# earlgrey register map
Vendor: lowRISC; File version: 0.1
CPU: ibex rev01, little endian, no MPU, no FPU, VTOR, 2 interrupt priority bits, 2 interrupts
Registers are 32-bit, read-write, no defined reset value unless marked. A register's access mark holds for its fields unless they carry their own. Offsets are from the block's base; [hi:lo] are bit positions.

## CSRNG — Takes entropy bits to produce cryptographically secure random numbers for consumption by hardware blocks and by software
Base 0x41150000
0x40 REGWEN — Register write enable for all control registers
  [0] Value — When true, all writeable registers can be modified.When false, they become read-only.
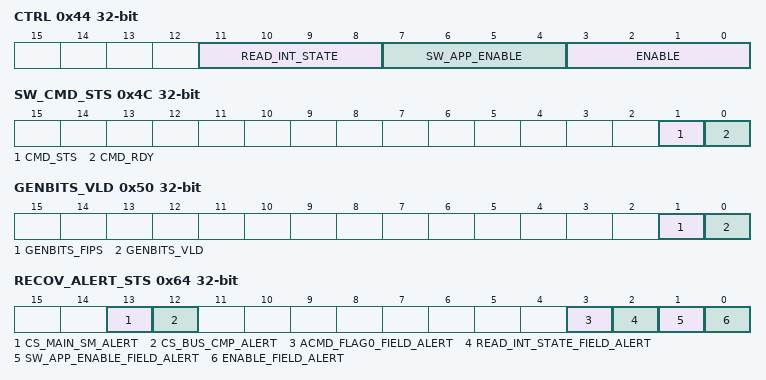
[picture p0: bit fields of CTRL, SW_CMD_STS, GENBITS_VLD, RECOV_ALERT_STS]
0x44 CTRL — Control register
  [11:8] READ_INT_STATE — Setting this field to kMultiBitBool4True will enable reading from the !!INT_STATE_VAL register.Reading the internal state of the enable instances will be enabledonly if the otp_en_csrng_sw_app_read input vector is set to the enable encoding.
  [7:4] SW_APP_ENABLE — Setting this field to kMultiBitBool4True will enable reading from the !!GENBITS register.This application interface for software (register based) will be enabledonly if the otp_en_csrng_sw_app_read input vector is set to the enable encoding.
  [3:0] ENABLE — Setting this field to kMultiBitBool4True will enable the CSRNG module. The modulesof the entropy complex may only be enabled and disabled in a specific order, seeProgrammers Guide for details.
0x48 CMD_REQ wo — Command request register
  [31:0] CMD_REQ — Writing this request with defined CSRNG commands will initiate allpossible CSRNG actions. The application interface must wait for the"ack" to return before issuing new commands.
0x4C SW_CMD_STS ro — Application interface command status register
  [1] CMD_STS — This one bit field is the status code returned with the application command ack.It is updated each time a command ack is asserted on the internal applicationinterface for software use.0b0: Request completed successfully0b1: Request completed with an error
  [0] CMD_RDY — This bit indicates when the command interface is ready to accept commands.
0x50 GENBITS_VLD ro — Generate bits returned valid register
  [1] GENBITS_FIPS — This bit is set when genbits are FIPS/CC compliant.
  [0] GENBITS_VLD — This bit is set when genbits are available on this application interface.
0x54 GENBITS ro — Generate bits returned register
  [31:0] GENBITS — Reading this register will get the generated bits that were requested withthe generate request. This register must be four times for each requestnumber made. For example, a application command generate request witha `creq` value of 4 requires this register to be read 16 times to get allof the data out of the FIFO path.
0x58 INT_STATE_NUM — Internal state number register
  [3:0] INT_STATE_NUM — Setting this field will set the number for which internal state can beselected for a read access. Up to 16 internal state values can be chosenfrom this register. The actual number of valid internal state fieldsis set by parameter NHwApps plus 1 software app. For those selections that pointto reserved locations (greater than NHwApps plus 1), the returned valuewill be zero. Writing this register will also reset the internal readpointer for the !!INT_STATE_VAL register.Note: This register should be read back after being written to ensurethat the !!INT_STATE_VAL read back is accurate.
0x5C INT_STATE_VAL ro — Internal state read access register
  [31:0] INT_STATE_VAL — Reading this register will dump out the contents of the selected internal state field.Since the internal state field is 448 bits wide, it will require 14 reads from thisregister to gather the entire field. Once 14 reads have been done, the internal readpointer (selects 32 bits of the 448 bit field) will reset to zero. The !!INT_STATE_NUMcan be re-written at this time (internal read pointer is also reset), and thenanother internal state field can be read.
0x60 HW_EXC_STS — Hardware instance exception status register
  [15:0] HW_EXC_STS — Reading this register indicates whether one of the CSRNG HW instances hasencountered an exception. Each bit corresponds to a particular hardwareinstance, with bit 0 corresponding to instance HW0, bit 1 correspondingto instance HW1, and so forth. (To monitor the status of requests madeto the SW instance, check the !!SW_CMD_STS register). Writing a zero to this registerresets the status bits.
0x64 RECOV_ALERT_STS — Recoverable alert status register
  [13] CS_MAIN_SM_ALERT — This bit is set when an unsupported/illegal CSRNG command is being processed.The main FSM will hang unless the module enable field is set to the disabled state.
  [12] CS_BUS_CMP_ALERT — This bit is set when the software application port genbits bus value is equalto the prior valid value on the bus, indicating a possible attack.Writing a zero resets this status bit.
  [3] ACMD_FLAG0_FIELD_ALERT — This bit is set when the FLAG0 field in the Application Command is set toa value other than kMultiBitBool4True or kMultiBitBool4False.Writing a zero resets this status bit.
  [2] READ_INT_STATE_FIELD_ALERT — This bit is set when the READ_INT_STATE field in the !!CTRL register is set toa value other than kMultiBitBool4True or kMultiBitBool4False.Writing a zero resets this status bit.
  [1] SW_APP_ENABLE_FIELD_ALERT — This bit is set when the SW_APP_ENABLE field in the !!CTRL register is set toa value other than kMultiBitBool4True or kMultiBitBool4False.Writing a zero resets this status bit.
  [0] ENABLE_FIELD_ALERT — This bit is set when the ENABLE field in the !!CTRL register is set toa value other than kMultiBitBool4True or kMultiBitBool4False.Writing a zero resets this status bit.
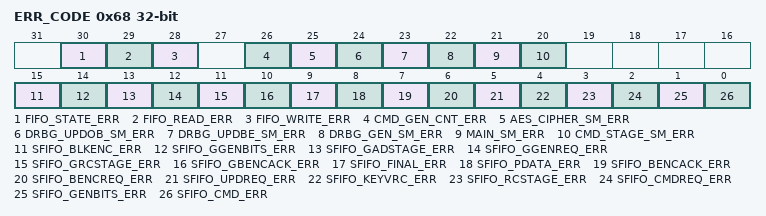
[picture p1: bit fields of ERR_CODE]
0x68 ERR_CODE ro — Hardware detection of error conditions status register
  [30] FIFO_STATE_ERR — This bit will be set to one when any of the source bits (bits 0 through 15 of thisthis register) are asserted as a result of an error pulse generated fromany FIFO where both the empty and full status bits are set.This bit will stay set until the next reset.
  [29] FIFO_READ_ERR — This bit will be set to one when any of the source bits (bits 0 through 15 of thisthis register) are asserted as a result of an error pulse generated fromany empty FIFO that has recieved a read pulse.This bit will stay set until the next reset.
  [28] FIFO_WRITE_ERR — This bit will be set to one when any of the source bits (bits 0 through 15 of thisthis register) are asserted as a result of an error pulse generated fromany full FIFO that has been recieved a write pulse.This bit will stay set until the next reset.
  [26] CMD_GEN_CNT_ERR — This bit will be set to one when a mismatch in any of the hardened countershas been detected.This error will signal a fatal alert, and alsoan interrupt if enabled.This bit will stay set until the next reset.
  [25] AES_CIPHER_SM_ERR — This bit will be set to one when an AES fatal error has been detected.This error will signal a fatal alert, and alsoan interrupt if enabled.This bit will stay set until the next reset.
  [24] DRBG_UPDOB_SM_ERR — This bit will be set to one when an illegal state has been detected for thectr_drbg update out block state machine. This error will signal a fatal alert, and alsoan interrupt if enabled.This bit will stay set until the next reset.
  [23] DRBG_UPDBE_SM_ERR — This bit will be set to one when an illegal state has been detected for thectr_drbg update block encode state machine. This error will signal a fatal alert, and alsoan interrupt if enabled.This bit will stay set until the next reset.
  [22] DRBG_GEN_SM_ERR — This bit will be set to one when an illegal state has been detected for thectr_drbg gen state machine. This error will signal a fatal alert, and alsoan interrupt if enabled.This bit will stay set until the next reset.
  [21] MAIN_SM_ERR — This bit will be set to one when an illegal state has been detected for themain state machine. This error will signal a fatal alert, and alsoan interrupt if enabled.This bit will stay set until the next reset.
  [20] CMD_STAGE_SM_ERR — This bit will be set to one when an illegal state has been detected for thecommand stage state machine. This error will signal a fatal alert, and alsoan interrupt if enabled.This bit will stay set until the next reset.
  [15] SFIFO_BLKENC_ERR — This bit will be set to one when an error has been detected for theblkenc FIFO. The type of error is reflected in the type statusbits (bits 28 through 30 of this register).This bit will stay set until the next reset.
  [14] SFIFO_GGENBITS_ERR — This bit will be set to one when an error has been detected for theggenbits FIFO. The type of error is reflected in the type statusbits (bits 28 through 30 of this register).This bit will stay set until the next reset.
  [13] SFIFO_GADSTAGE_ERR — This bit will be set to one when an error has been detected for thegadstage FIFO. The type of error is reflected in the type statusbits (bits 28 through 30 of this register).This bit will stay set until the next reset.
  [12] SFIFO_GGENREQ_ERR — This bit will be set to one when an error has been detected for theggenreq FIFO. The type of error is reflected in the type statusbits (bits 28 through 30 of this register).This bit will stay set until the next reset.
  [11] SFIFO_GRCSTAGE_ERR — This bit will be set to one when an error has been detected for thegrcstage FIFO. The type of error is reflected in the type statusbits (bits 28 through 30 of this register).This bit will stay set until the next reset.
  [10] SFIFO_GBENCACK_ERR — This bit will be set to one when an error has been detected for thegbencack FIFO. The type of error is reflected in the type statusbits (bits 28 through 30 of this register).This bit will stay set until the next reset.
  [9] SFIFO_FINAL_ERR — This bit will be set to one when an error has been detected for thefinal FIFO. The type of error is reflected in the type statusbits (bits 28 through 30 of this register).This bit will stay set until the next reset.
  [8] SFIFO_PDATA_ERR — This bit will be set to one when an error has been detected for thepdata FIFO. The type of error is reflected in the type statusbits (bits 28 through 30 of this register).This bit will stay set until the next reset.
  [7] SFIFO_BENCACK_ERR — This bit will be set to one when an error has been detected for thebencack FIFO. The type of error is reflected in the type statusbits (bits 28 through 30 of this register).This bit will stay set until the next reset.
  [6] SFIFO_BENCREQ_ERR — This bit will be set to one when an error has been detected for thebencreq FIFO. The type of error is reflected in the type statusbits (bits 28 through 30 of this register).This bit will stay set until the next reset.
  [5] SFIFO_UPDREQ_ERR — This bit will be set to one when an error has been detected for theupdreq FIFO. The type of error is reflected in the type statusbits (bits 28 through 30 of this register).This bit will stay set until the next reset.
  [4] SFIFO_KEYVRC_ERR — This bit will be set to one when an error has been detected for thekeyvrc FIFO. The type of error is reflected in the type statusbits (bits 28 through 30 of this register).This bit will stay set until the next reset.
  [3] SFIFO_RCSTAGE_ERR — This bit will be set to one when an error has been detected for thercstage FIFO. The type of error is reflected in the type statusbits (bits 28 through 30 of this register).This bit will stay set until the next reset.
  [2] SFIFO_CMDREQ_ERR — This bit will be set to one when an error has been detected for thecmdreq FIFO. The type of error is reflected in the type statusbits (bits 28 through 30 of this register).This bit will stay set until the next reset.
  [1] SFIFO_GENBITS_ERR — This bit will be set to one when an error has been detected for thecommand stage genbits FIFO. The type of error is reflected in the type statusbits (bits 28 through 30 of this register).This bit will stay set until the next reset.
  [0] SFIFO_CMD_ERR — This bit will be set to one when an error has been detected for thecommand stage command FIFO. The type of error is reflected in the type statusbits (bits 28 through 30 of this register).This bit will stay set until the next reset.
0x6C ERR_CODE_TEST — Test error conditions register
  [4:0] ERR_CODE_TEST — Setting this field will set the bit number for which an errorwill be forced in the hardware. This bit number is that same onefound in the !!ERR_CODE register. The action of writing thisregister will force an error pulse. The sole purpose of thisregister is to test that any error properly propagates to eitheran interrupt or an alert.
0x70 MAIN_SM_STATE ro — Main state machine state debug register
  [7:0] MAIN_SM_STATE — This is the state of the CSRNG main state machine.See the RTL file `csrng_main_sm` for the meaning of the values.
